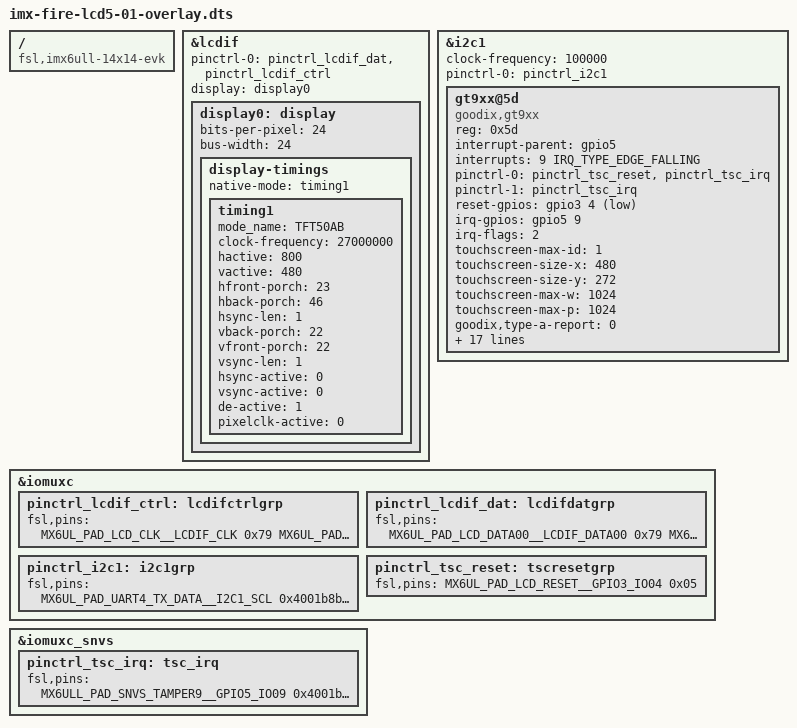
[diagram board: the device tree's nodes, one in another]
/*
 * Copyright (C) 2019 Seeed Technology Co,Ltd  - https://www.seeed.cc
 * Author: Baozhu Zuo <zuobaozhu@gmail.com>
 *
 * This program is free software; you can redistribute it and/or modify
 * it under the terms of the GNU General Public License version 2 as
 * published by the Free Software Foundation.
 */
#include "imx6ul-pinfunc.h"
#include "imx6ull-pinfunc-snvs.h"
#include "dt-bindings/interrupt-controller/irq.h"
#include "dt-bindings/gpio/gpio.h"
/dts-v1/;
/plugin/;

/ {
     compatible = "fsl,imx6ull-14x14-evk", "fsl,imx6ull";

        fragment@0 {
                target = <&lcdif>;
                __overlay__ {
                    pinctrl-names = "default";
                    pinctrl-0 = <&pinctrl_lcdif_dat &pinctrl_lcdif_ctrl>;
                    display = <&display0>;
                    status = "okay";

                	display0: display {
                		bits-per-pixel = <24>;
                		bus-width = <24>;

                		display-timings {
                			native-mode = <&timing1>;

                			timing1: timing1 {
                                mode_name = "TFT50AB";
                                clock-frequency = <27000000>;
                                hactive = <800>;
                                vactive = <480>;
                                hfront-porch = <23>;
                                hback-porch = <46>;
                                hsync-len = <1>;
                                vback-porch = <22>;
                                vfront-porch = <22>;
                                vsync-len = <1>;
                    
                                hsync-active = <0>;
                                vsync-active = <0>;
                                de-active = <1>;
                                pixelclk-active = <0>;
                			};
                		};
                	};
                };
            };
        fragment@1 {
            target = <&i2c1>;
            __overlay__ {
            	clock-frequency = <100000>;
            	pinctrl-names = "default";
            	pinctrl-0 = <&pinctrl_i2c1>;
            	status = "okay";     
                
                #address-cells = <1>;
                #size-cells = <0>;     
            	gt9xx@5d {
            		compatible = "goodix,gt9xx";
            		reg = <0x5d>;
            		status = "okay";
            		interrupt-parent = <&gpio5>;
            		interrupts = <9 IRQ_TYPE_EDGE_FALLING>;
            		pinctrl-names = "default";
            		pinctrl-0 = <&pinctrl_tsc_reset &pinctrl_tsc_irq>;
            		pinctrl-1 = <&pinctrl_tsc_irq>;
            		/*pinctrl-names = "default", "int-output-low", "int-output-high", "int-input";
            		pinctrl-0 = <&ts_int_default>;
            		pinctrl-1 = <&ts_int_output_low>;
            		pinctrl-2 = <&ts_int_output_high>;
            		pinctrl-3 = <&ts_int_input>;
            		*/
            		reset-gpios = <&gpio3 4 GPIO_ACTIVE_LOW>;
            		irq-gpios = <&gpio5 9 IRQ_TYPE_EDGE_FALLING>;
            		irq-flags = <2>;		/*1:rising 2: falling*/

            		touchscreen-max-id = <1>;
            		touchscreen-size-x = <480>;
            		touchscreen-size-y = <272>;
            		touchscreen-max-w = <1024>;
            		touchscreen-max-p = <1024>;
            		/*touchscreen-key-map = <172>, <158>;*/ /*KEY_HOMEPAGE, KEY_BACK*/

            		goodix,type-a-report = <0>;
            		goodix,driver-send-cfg = <0>;
            		goodix,create-wr-node = <1>;
            		goodix,wakeup-with-reset = <0>;
            		goodix,resume-in-workqueue = <0>;
            		goodix,int-sync = <1>;
            		goodix,swap-x2y = <0>;
            		goodix,esd-protect = <0>;
            		goodix,pen-suppress-finger = <0>;
            		goodix,auto-update = <0>;
            		goodix,auto-update-cfg = <0>;
            		goodix,power-off-sleep = <0>;

            		/*7*/
            		goodix,cfg-group0 = [
            		00 20 03 E0 01 05 0D 00 01 08
            		28 0F 50 32 03 05 00 00 00 00
            		00 00 00 00 00 00 00 8A 2A 0C
            		45 47 0C 08 00 00 00 02 02 2D
            		00 00 00 00 00 03 64 32 00 00
            		00 28 64 94 C5 02 07 00 00 04
            		9C 2C 00 8F 34 00 84 3F 00 7C
            		4C 00 77 5B 00 77 00 00 00 00
            		00 00 00 00 00 00 00 00 00 00
            		00 00 00 00 00 00 00 00 00 00
            		00 00 00 00 00 00 00 00 00 00
            		00 00 18 16 14 12 10 0E 0C 0A
            		08 06 04 02 FF FF 00 00 00 00
            		00 00 00 00 00 00 00 00 00 00
            		00 00 16 18 1C 1D 1E 1F 20 21
            		22 24 13 12 10 0F 0A 08 06 04
            		02 00 FF FF FF FF FF FF 00 00
            		00 00 00 00 00 00 00 00 00 00
            		00 00 00 00 24 01
            		];

            		/*4.3*/
            		goodix,cfg-group1 = [
            		97 E0 01 10 01 05 0D 00 01 00
            		00 05 5A 46 53 11 00 00 11 11
            		14 14 14 22 0A 04 00 00 00 00
            		00 00 53 00 14 00 00 84 00 00
            		3C 00 00 64 1E 28 87 27 08 32
            		34 05 0D 20 33 60 11 02 24 00
            		00 64 80 80 14 02 00 00 54 89
            		68 85 6D 82 72 80 76 7D 7B 7B
            		00 00 00 00 00 00 00 F0 50 3C
            		FF FF 07 00 00 00 02 14 14 03
            		04 00 21 64 0A 00 00 00 00 00
            		00 00 00 00 00 00 00 00 00 00
            		00 00 00 00 00 00 00 00 00 00
            		32 20 50 3C 3C 00 00 00 00 00
            		0D 06 0C 05 0B 04 0A 03 FF FF
            		FF FF FF FF 00 01 02 03 04 05
            		06 07 08 09 0A 0B 0C 0D FF FF
            		FF FF FF FF FF FF FF FF FF FF
            		00 00 00 00 00 00 00 00 00 00
            		00 00 00 00 3C 00 05 1E 00 02
            		2A 1E 19 14 02 00 03 0A 05 00
            		00 00 00 00 00 00 01 FF FF 86
            		22 03 00 00 33 00 0F 00 00 00
            		50 3C 50 00 00 00 00 2A 01
            		];

            		/*5*/
            		goodix,cfg-group2 = [
            		00 20 03 E0 01 05 3C 00 01 08
            		28 0C 50 32 03 05 00 00 00 00
            		00 00 00 17 19 1E 14 8B 2B 0D
            		33 35 0C 08 00 00 00 9A 03 11
            		00 01 00 00 00 00 00 32 00 00
            		00 20 58 94 C5 02 00 00 00 04
            		B0 23 00 93 2B 00 7B 35 00 69
            		41 00 5B 4F 00 5B 00 00 00 00
            		00 00 00 00 00 00 00 00 00 00
            		00 00 00 00 00 00 00 00 00 00
            		00 00 00 00 00 00 00 00 00 00
            		00 00 02 04 06 08 0A 0C 0E 10
            		12 14 16 18 1A FF 00 00 00 00
            		00 00 00 00 00 00 00 00 00 00
            		00 00 00 02 04 06 08 0A 0C 0F
            		10 12 13 16 18 1C 1D 1E 1F 20
            		21 22 24 26 FF FF FF FF 00 00
            		00 FF FF FF FF FF FF FF FF FF
            		FF FF FF FF 48 01
            		];
            	};      
            };
        };
        fragment@2 {
                target = <&iomuxc>;
                __overlay__ {
                    pinctrl_lcdif_ctrl: lcdifctrlgrp {
                        fsl,pins = <
                            MX6UL_PAD_LCD_CLK__LCDIF_CLK	    0x79
                            MX6UL_PAD_LCD_ENABLE__LCDIF_ENABLE  0x79
                            MX6UL_PAD_LCD_HSYNC__LCDIF_HSYNC    0x79
                            MX6UL_PAD_LCD_VSYNC__LCDIF_VSYNC    0x79
                        >;
                    };
                    pinctrl_lcdif_dat: lcdifdatgrp {
                        fsl,pins = <
                            MX6UL_PAD_LCD_DATA00__LCDIF_DATA00  0x79
                            MX6UL_PAD_LCD_DATA01__LCDIF_DATA01  0x79
                            MX6UL_PAD_LCD_DATA02__LCDIF_DATA02  0x79
                            MX6UL_PAD_LCD_DATA03__LCDIF_DATA03  0x79
                            MX6UL_PAD_LCD_DATA04__LCDIF_DATA04  0x79
                            MX6UL_PAD_LCD_DATA05__LCDIF_DATA05  0x79
                            MX6UL_PAD_LCD_DATA06__LCDIF_DATA06  0x79
                            MX6UL_PAD_LCD_DATA07__LCDIF_DATA07  0x79
                            MX6UL_PAD_LCD_DATA08__LCDIF_DATA08  0x79
                            MX6UL_PAD_LCD_DATA09__LCDIF_DATA09  0x79
                            MX6UL_PAD_LCD_DATA10__LCDIF_DATA10  0x79
                            MX6UL_PAD_LCD_DATA11__LCDIF_DATA11  0x79
                            MX6UL_PAD_LCD_DATA12__LCDIF_DATA12  0x79
                            MX6UL_PAD_LCD_DATA13__LCDIF_DATA13  0x79
                            MX6UL_PAD_LCD_DATA14__LCDIF_DATA14  0x79
                            MX6UL_PAD_LCD_DATA15__LCDIF_DATA15  0x79
                            MX6UL_PAD_LCD_DATA16__LCDIF_DATA16  0x79
                            MX6UL_PAD_LCD_DATA17__LCDIF_DATA17  0x79
                            MX6UL_PAD_LCD_DATA18__LCDIF_DATA18  0x79
                            MX6UL_PAD_LCD_DATA19__LCDIF_DATA19  0x79
                            MX6UL_PAD_LCD_DATA20__LCDIF_DATA20  0x79
                            MX6UL_PAD_LCD_DATA21__LCDIF_DATA21  0x79
                            MX6UL_PAD_LCD_DATA22__LCDIF_DATA22  0x79
                            MX6UL_PAD_LCD_DATA23__LCDIF_DATA23  0x79
                        >;
                    };
                pinctrl_i2c1: i2c1grp {
                    fsl,pins = <
                        MX6UL_PAD_UART4_TX_DATA__I2C1_SCL 0x4001b8b0
                        MX6UL_PAD_UART4_RX_DATA__I2C1_SDA 0x4001b8b0
                    >;
                };

                pinctrl_tsc_reset: tscresetgrp {
                    fsl,pins = <
                        /* used for tsc reset */
                        MX6UL_PAD_LCD_RESET__GPIO3_IO04		0x05
                    >;
                };
            };
        };
        fragment@3 {
            target = <&iomuxc_snvs>;
            __overlay__ {
                pinctrl_tsc_irq: tsc_irq {
                    fsl,pins = <
                        MX6ULL_PAD_SNVS_TAMPER9__GPIO5_IO09        0x4001b8b0
                    >;
                };
            };
        };
};

